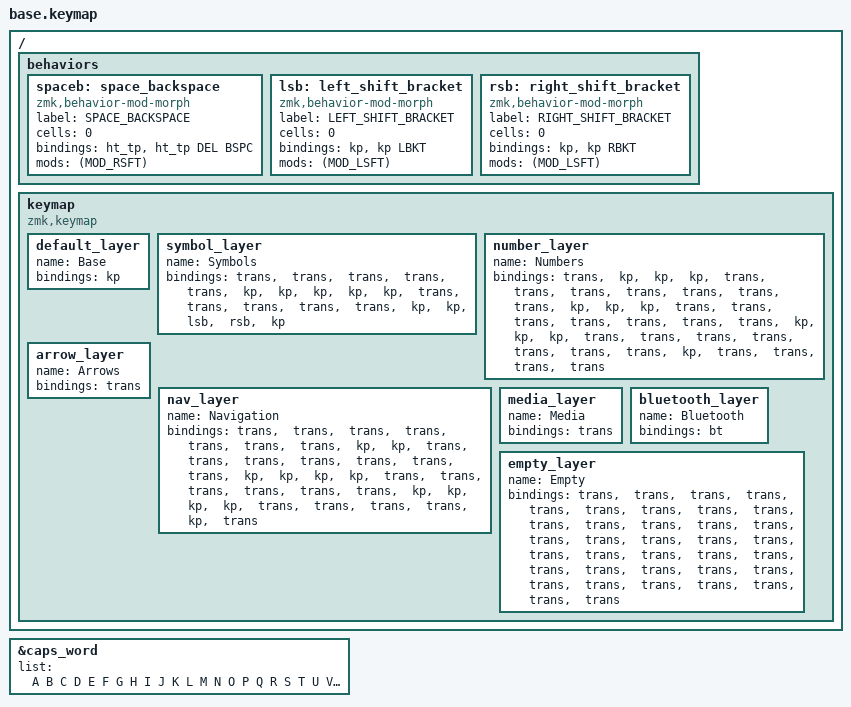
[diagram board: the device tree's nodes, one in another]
/*
 * Base keymap for ZMK keyboards
 *
 * This file defines the base layer and common layers used across different
 * keyboards. It includes homerow mods, layer tap behaviors, and custom key
 * combinations.
 */

#include <behaviors.dtsi>
#include <dt-bindings/zmk/bt.h>
#include <dt-bindings/zmk/keys.h>

// Layer Definitions
#define SYMBOLS 1
#define NUMBERS 2
#define ARROWS 3
#define NAV 4
#define MEDIA 5
#define BLUETOOTH 6

// Keycode Definitions
#define HYP LS(LC(LA(LGUI)))
#define HYPER(key) LS(LC(LA(LG(key))))
#define MEH(key) LS(LC(LA(key)))

&caps_word {
  continue - list = <A B C D E F G H I J K L M N O P Q R S T U V W X Y Z
                         UNDERSCORE MINUS BSPC DEL SYMBOLS>;
};

/ {
  behaviors {
  spaceb:
    space_backspace {
      compatible = "zmk,behavior-mod-morph";
      label = "SPACE_BACKSPACE";
#binding - cells = < 0>;
      bindings = <&ht_tp>, <&ht_tp DEL BSPC>;
      mods = <(MOD_RSFT)>;
    };

  lsb:
    left_shift_bracket {
      compatible = "zmk,behavior-mod-morph";
      label = "LEFT_SHIFT_BRACKET";
#binding - cells = < 0>;
      bindings = <&kp>, <&kp LBKT>;
      mods = <(MOD_LSFT)>;
    };

  rsb:
    right_shift_bracket {
      compatible = "zmk,behavior-mod-morph";
      label = "RIGHT_SHIFT_BRACKET";
#binding - cells = < 0>;
      bindings = <&kp>, <&kp RBKT>;
      mods = <(MOD_LSFT)>;
    };
  };

  // Keymap Template
  //
  // | SW2  | SW3  | SW4  | SW5  | SW6  |   | SW6  | SW5  | SW4  | SW3  | SW2  |
  // | SW8  | SW9  | SW10 | SW11 | SW12 |   | SW12 | SW11 | SW10 | SW9  | SW8  |
  // | SW14 | SW15 | SW16 | SW17 | SW18 |   | SW18 | SW17 | SW16 | SW15 | SW14 |
  //               | SW19 | SW20 | SW21 |   | SW21 | SW20 | SW19 |

  keymap {
    compatible = "zmk,keymap";

    default_layer {
      display - name = "Base";
      bindings = <&kp>;
    };

    symbol_layer {
      display - name = "Symbols";
      bindings =
          <&trans & trans & trans & trans & trans & kp & kp & kp & kp & kp &
           trans & trans & trans & trans & trans & kp & kp & lsb & rsb & kp> |
          |
          //`---------------------------+-------------------------'
          //`---------------------------+-------------------------'
          &trans & trans & trans & trans & trans & trans & trans & kp LT &
              kp GT & trans //,---------------------+-----------------------.
                            //,----------------------+--------------------. | |
                            //|     |           | DEL | TAB |     |
                            //`-------------------------------------------'
                            //`------------------------------------------'
              & trans & trans & trans & ht_tp DEL BSPC & kp TAB & trans > ;
    };

    number_layer {
      display - name = "Numbers";
      bindings =
          <&trans & kp & kp & kp & trans & trans & trans & trans & trans &
           trans & trans & kp & kp & kp & trans & trans & trans & trans &
           trans & trans & trans & kp & kp & kp & trans & trans & trans &
           trans & trans & trans & trans & kp & trans & trans & trans & trans>;
    };

    arrow_layer {
      display - name = "Arrows";
      bindings = <&trans>;
    };

    nav_layer {
      display - name = "Navigation";
      bindings =
          <&trans & trans & trans & trans & trans & trans & trans & kp & kp &
           trans & trans & trans & trans & trans & trans & trans & kp & kp &
           kp & kp & trans & trans & trans & trans & trans & trans & kp & kp &
           kp & kp & trans & trans & trans & trans & kp & trans>;
    };

    media_layer {
      display - name = "Media";
      bindings = <&trans>;
    };

    bluetooth_layer {
      display - name = "Bluetooth";
      bindings = <&bt>;
    };

    empty_layer {
      display - name = "Empty";
      bindings =
          <&trans & trans & trans & trans & trans & trans & trans & trans &
           trans & trans & trans & trans & trans & trans & trans & trans &
           trans & trans & trans & trans & trans & trans & trans & trans &
           trans & trans & trans & trans & trans & trans & trans & trans &
           trans & trans & trans & trans>;
    };
  };
};
